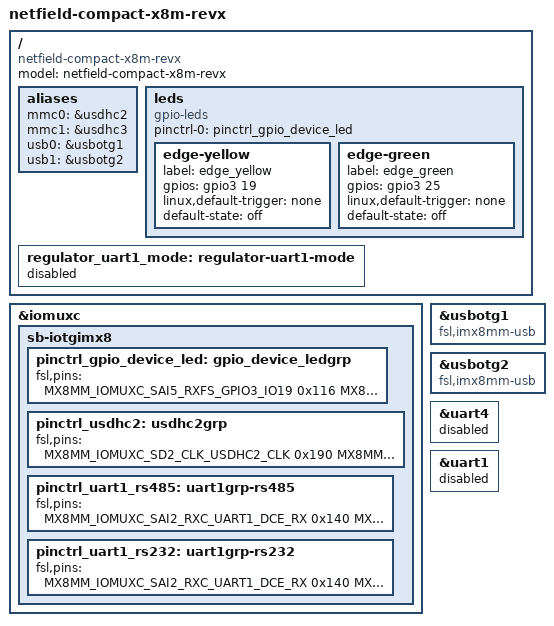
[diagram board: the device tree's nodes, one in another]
#include "../compulab/sb-iotgimx8.dts"

/ {
	model = "netfield-compact-x8m-revx";
	compatible = "netfield-compact-x8m-revx", "cpl,ucm-imx8m-mini", "fsl,imx8mm";

	aliases {
		mmc0 = &usdhc2; /* SD-Card */
		mmc1 = &usdhc3; /* eMMC */
		/delete-property/ mmc2;

		usb0 = &usbotg1;
		usb1 = &usbotg2;
	};

	leds {
		compatible = "gpio-leds";
		pinctrl-names = "default";
		pinctrl-0 = <&pinctrl_gpio_device_led>;
		edge-yellow {
			label = "edge_yellow";
			gpios = <&gpio3 19 GPIO_ACTIVE_HIGH>;
			linux,default-trigger = "none";
			default-state = "off";
		};
		edge-green {
			label = "edge_green";
			gpios = <&gpio3 25 GPIO_ACTIVE_HIGH>;
			linux,default-trigger = "none";
			default-state = "off";
		};
	};
};

&iomuxc {
	sb-iotgimx8 {
		pinctrl_gpio_device_led: gpio_device_ledgrp {
			fsl,pins = <
				MX8MM_IOMUXC_SAI5_RXFS_GPIO3_IO19	0x116
				MX8MM_IOMUXC_SAI5_MCLK_GPIO3_IO25	0x116
			>;
		};
	};
};

/* -------------------------------------------------------------------------- */
// NOTE:
//   Required fixes of sb-iotgimx8.dts ...

&iomuxc {
	sb-iotgimx8 {
		/* overwrite usdhc2grp setup by sb-iotgimx8.dts, sd-card access with previous setup fails with IO error */
		pinctrl_usdhc2: usdhc2grp {
			fsl,pins = <
				MX8MM_IOMUXC_SD2_CLK_USDHC2_CLK         0x190
				MX8MM_IOMUXC_SD2_CMD_USDHC2_CMD         0x1d0
				MX8MM_IOMUXC_SD2_DATA0_USDHC2_DATA0     0x1d0
				MX8MM_IOMUXC_SD2_DATA1_USDHC2_DATA1     0x1d0
				MX8MM_IOMUXC_SD2_DATA2_USDHC2_DATA2     0x1d0
				MX8MM_IOMUXC_SD2_DATA3_USDHC2_DATA3     0x1d0
				MX8MM_IOMUXC_GPIO1_IO04_USDHC2_VSELECT  0x1d0
			>;
		};
	};
};

&usbotg1 {
	/* u-boot only recognizes "fsl,imx27-usb" which is missing in kernel device-tree */
	compatible = "fsl,imx8mm-usb", "fsl,imx7d-usb", "fsl,imx27-usb";
};

&usbotg2 {
	/* u-boot only recognizes "fsl,imx27-usb" which is missing in kernel device-tree */
	compatible = "fsl,imx8mm-usb", "fsl,imx7d-usb", "fsl,imx27-usb";
};

&uart4 { /* bluetooth */
	status = "disabled";
};

/* -------------------------------------------------------------------------- */
// NOTE:
//   This enables the uart1 mode selection (RS485/RS232) by device-tree overlays.

/ {
	regulator_uart1_mode: regulator-uart1-mode {
		/delete-property/ enable-active-high;
		status = "disabled";
	};
};

&uart1 {
	/delete-property/ pinctrl-names;
	/delete-property/ pinctrl-0;

	/delete-property/ linux,rs485-enabled-at-boot-time;
	/delete-property/ rs485-rts-active-high;
	/delete-property/ rts-gpios;

	status = "disabled";
};

&iomuxc {
	sb-iotgimx8 {
		/delete-node/ uart1grp;

		pinctrl_uart1_rs485: uart1grp-rs485 {
			fsl,pins = <
				MX8MM_IOMUXC_SAI2_RXC_UART1_DCE_RX 0x140
				MX8MM_IOMUXC_SAI2_RXFS_UART1_DCE_TX 0x140
				MX8MM_IOMUXC_SAI2_TXFS_GPIO4_IO24 0x140 /* RTS */
				MX8MM_IOMUXC_SAI2_RXD0_UART1_DCE_RTS_B 0x140 /* CTS */
			>;
		};

		pinctrl_uart1_rs232: uart1grp-rs232 {
			fsl,pins = <
				MX8MM_IOMUXC_SAI2_RXC_UART1_DCE_RX	0x140
				MX8MM_IOMUXC_SAI2_RXFS_UART1_DCE_TX	0x140
				MX8MM_IOMUXC_SAI2_TXFS_UART1_DCE_CTS_B 0x140 /* RTS */
				MX8MM_IOMUXC_SAI2_RXD0_UART1_DCE_RTS_B	0x140 /* CTS */
			>;
		};
	};
};

/* -------------------------------------------------------------------------- */

// Add support for Industrial I/O add-on modules
#include "netfield-compact-x8m-revx-ied.dtsi"
#include "netfield-compact-x8m-revx-can.dtsi"
#include "netfield-compact-x8m-revx-poed.dtsi"
